# N32G41x register map
Vendor: Nsingtech Ltd.; File version: 1.0
CPU: CM4 r0p1, little endian, no MPU, no FPU, 4 interrupt priority bits
Registers are 32-bit, read-write, reset 0x0 unless marked. A register's access mark holds for its fields unless they carry their own. Offsets are from the block's base; [hi:lo] are bit positions; {n}, {i} and the like mark numbered series.

## GPIOC — GPIO Port C
Base 0x40021600
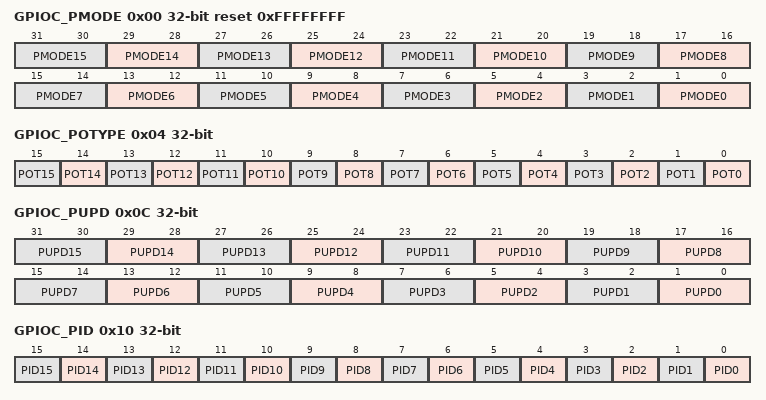
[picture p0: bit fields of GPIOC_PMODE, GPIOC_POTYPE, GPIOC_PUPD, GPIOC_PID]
0x00 GPIOC_PMODE reset 0xFFFFFFFF — GPIOC Port Mode Register
  [2n+1:2n] PMODE{n} (n=0..15) — Port C mode for pin {n}
0x04 GPIOC_POTYPE — GPIOC Port Output Type Register
  [n] POT{n} (n=0..15) — Port C output type for pin {n}
0x0C GPIOC_PUPD — GPIOC Port Pull-Up/Pull-Down Register
  [2n+1:2n] PUPD{n} (n=0..15) — Port C pull-up/pull-down for pin {n}
0x10 GPIOC_PID ro — GPIOC Port Input Data Register
  [n] PID{n} (n=0..15) — Port C input data for pin {n}
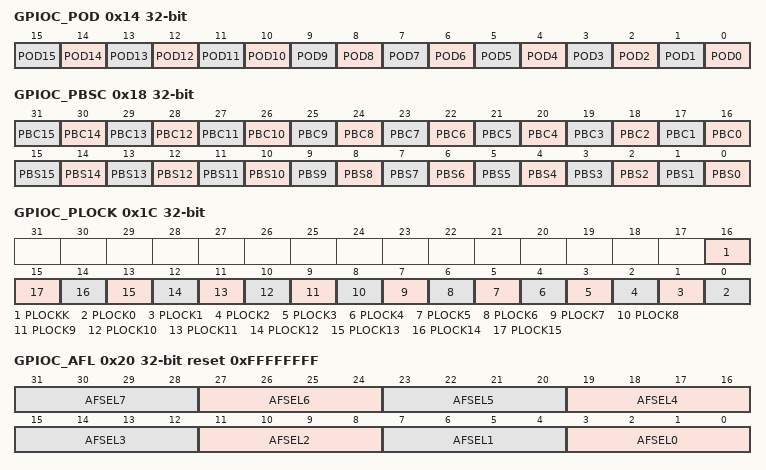
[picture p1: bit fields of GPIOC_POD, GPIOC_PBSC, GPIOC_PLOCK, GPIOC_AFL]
0x14 GPIOC_POD — GPIOC Port Output Data Register
  [n] POD{n} (n=0..15) — Port C output data for pin {n}
0x18 GPIOC_PBSC wo — GPIOC Port Bit Set/Clear Register
  [n+16] PBC{n} (n=0..15) — Port C clear bit {n}
  [n] PBS{n} (n=0..15) — Port C set bit {n}
0x1C GPIOC_PLOCK — GPIOC Port Configuration Lock Register
  [16] PLOCKK — Port configuration lock key
  [n] PLOCK{n} (n=0..15) — Port C configuration lock for pin {n}
0x20 GPIOC_AFL reset 0xFFFFFFFF — GPIOC Alternate Function Low Register
  [4n+3:4n] AFSEL{n} (n=0..7) — Port C alternate function for pin {n}
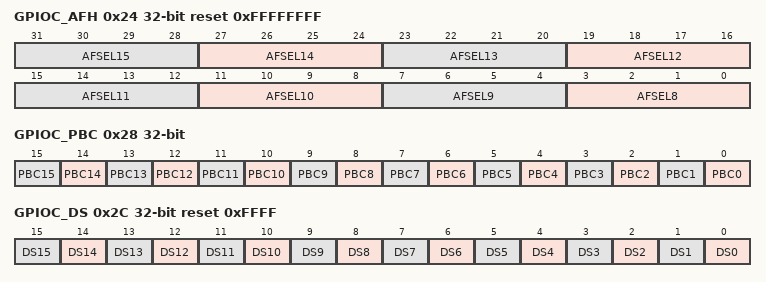
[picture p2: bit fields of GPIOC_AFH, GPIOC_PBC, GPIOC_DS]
0x24 GPIOC_AFH reset 0xFFFFFFFF — GPIOC Alternate Function High Register
  [4n-29:4n-32] AFSEL{n} (n=8..15) — Port C alternate function for pin {n}
0x28 GPIOC_PBC wo — GPIOC Port Bit Clear Register
  [n] PBC{n} (n=0..15) — Port C clear output bit {n}
0x2C GPIOC_DS reset 0xFFFF — GPIOC Drive Strength Register
  [n] DS{n} (n=0..15) — Port C drive strength for pin {n}

## GPIOD — GPIO Port D
Base 0x40021700
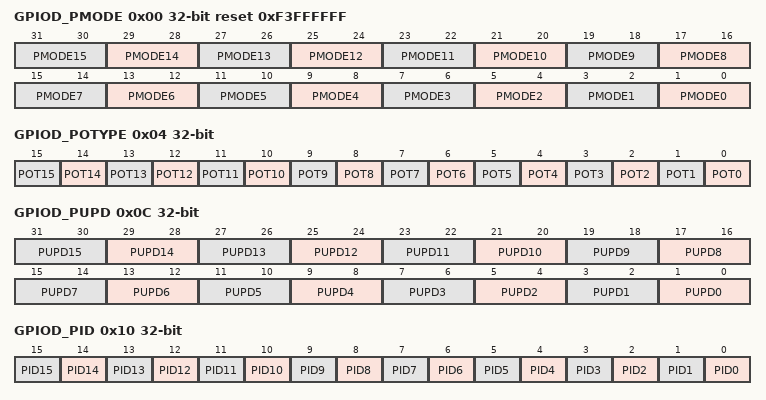
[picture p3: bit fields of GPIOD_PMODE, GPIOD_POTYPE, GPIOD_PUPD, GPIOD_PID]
0x00 GPIOD_PMODE reset 0xF3FFFFFF — GPIOD Port Mode Register
  [2n+1:2n] PMODE{n} (n=0..15) — Port D mode for pin {n}
0x04 GPIOD_POTYPE — GPIOD Port Output Type Register
  [n] POT{n} (n=0..15) — Port D output type for pin {n}
0x0C GPIOD_PUPD — GPIOD Port Pull-Up/Pull-Down Register
  [2n+1:2n] PUPD{n} (n=0..15) — Port D pull-up/pull-down for pin {n}
0x10 GPIOD_PID ro — GPIOD Port Input Data Register
  [n] PID{n} (n=0..15) — Port D input data for pin {n}
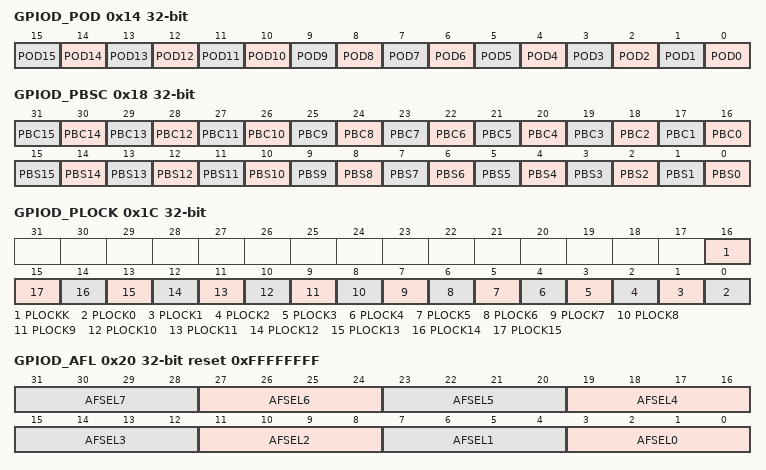
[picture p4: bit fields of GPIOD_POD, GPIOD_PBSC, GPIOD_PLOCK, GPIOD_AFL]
0x14 GPIOD_POD — GPIOD Port Output Data Register
  [n] POD{n} (n=0..15) — Port D output data for pin {n}
0x18 GPIOD_PBSC wo — GPIOD Port Bit Set/Clear Register
  [n+16] PBC{n} (n=0..15) — Port D clear bit {n}
  [n] PBS{n} (n=0..15) — Port D set bit {n}
0x1C GPIOD_PLOCK — GPIOD Port Configuration Lock Register
  [16] PLOCKK — Port configuration lock key
  [n] PLOCK{n} (n=0..15) — Port D configuration lock for pin {n}
0x20 GPIOD_AFL reset 0xFFFFFFFF — GPIOD Alternate Function Low Register
  [4n+3:4n] AFSEL{n} (n=0..7) — Port D alternate function for pin {n}
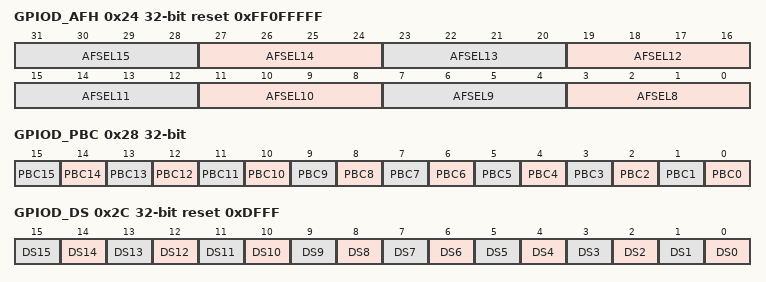
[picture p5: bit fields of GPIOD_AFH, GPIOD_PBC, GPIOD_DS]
0x24 GPIOD_AFH reset 0xFF0FFFFF — GPIOD Alternate Function High Register
  [4n-29:4n-32] AFSEL{n} (n=8..15) — Port D alternate function for pin {n}
0x28 GPIOD_PBC wo — GPIOD Port Bit Clear Register
  [n] PBC{n} (n=0..15) — Port D clear output bit {n}
0x2C GPIOD_DS reset 0xDFFF — GPIOD Drive Strength Register
  [n] DS{n} (n=0..15) — Port D drive strength for pin {n}

## AFIO — Alternate Function I/O
Base 0x40021800
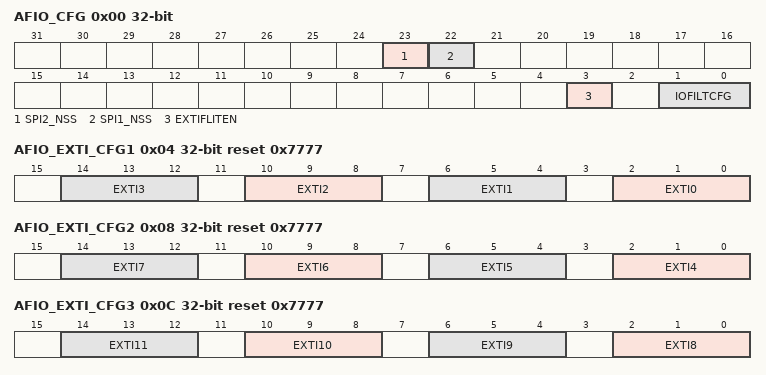
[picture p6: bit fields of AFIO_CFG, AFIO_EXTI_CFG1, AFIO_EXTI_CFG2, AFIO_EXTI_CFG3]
0x00 AFIO_CFG — AFIO Configuration Register
  [23] SPI2_NSS — SPI2 NSS mode
  [22] SPI1_NSS — SPI1 NSS mode
  [3] EXTIFLITEN — EXTI line filter enable
  [1:0] IOFILTCFG — IO filter control
0x04 AFIO_EXTI_CFG1 reset 0x7777 — AFIO EXTI Configuration Register 1
  [4n+2:4n] EXTI{n} (n=0..3) — EXTI{n} configuration
0x08 AFIO_EXTI_CFG2 reset 0x7777 — AFIO EXTI Configuration Register 2
  [4n-14:4n-16] EXTI{n} (n=4..7) — EXTI{n} configuration
0x0C AFIO_EXTI_CFG3 reset 0x7777 — AFIO EXTI Configuration Register 3
  [4n-30:4n-32] EXTI{n} (n=8..11) — EXTI{n} configuration
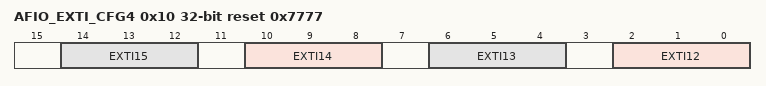
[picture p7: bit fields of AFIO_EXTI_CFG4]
0x10 AFIO_EXTI_CFG4 reset 0x7777 — AFIO EXTI Configuration Register 4
  [4n-46:4n-48] EXTI{n} (n=12..15) — EXTI{n} configuration
0x14 AFIO_DIGEFT_CFG1 — AFIO PA Digital Filter Configuration Register
  [15:0] DIGEFTEN — PA digital filter enable
0x18 AFIO_DIGEFT_CFG2 — AFIO PB Digital Filter Configuration Register
  [15:0] DIGEFTEN — PB digital filter enable
0x1C AFIO_DIGEFT_CFG3 — AFIO PC Digital Filter Configuration Register
  [15:0] DIGEFTEN — PC digital filter enable
0x20 AFIO_DIGEFT_CFG4 — AFIO PD Digital Filter Configuration Register
  [15:0] DIGEFTEN — PD digital filter enable

## PWR — Power Control
Base 0x40007000
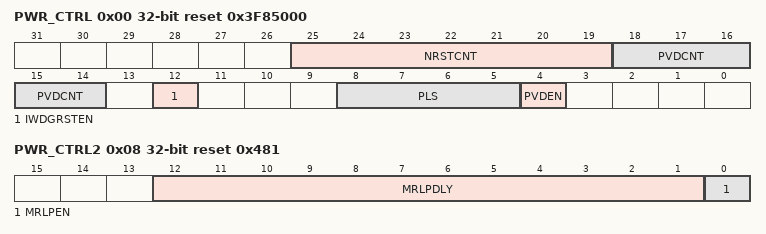
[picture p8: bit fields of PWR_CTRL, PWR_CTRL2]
0x00 PWR_CTRL reset 0x3F85000 — PWR Control Register
  [25:19] NRSTCNT — NRST pin filter width
  [18:14] PVDCNT — PVD filter width
  [12] IWDGRSTEN — IWDG reset enable control
  [8:5] PLS — PVD alarm voltage level selection
  [4] PVDEN — PVD enable control
0x04 PWR_CTRLSTS ro — PWR Control/Status Register
  [2] PVDO — PVD module detection output
0x08 PWR_CTRL2 reset 0x481 — PWR Control Register 2
  [12:1] MRLPDLY — MR LP control delay
  [0] MRLPEN — MR LOWPOWER mode control

## FLASH — FLASH Memory Controller
Base 0x40022000
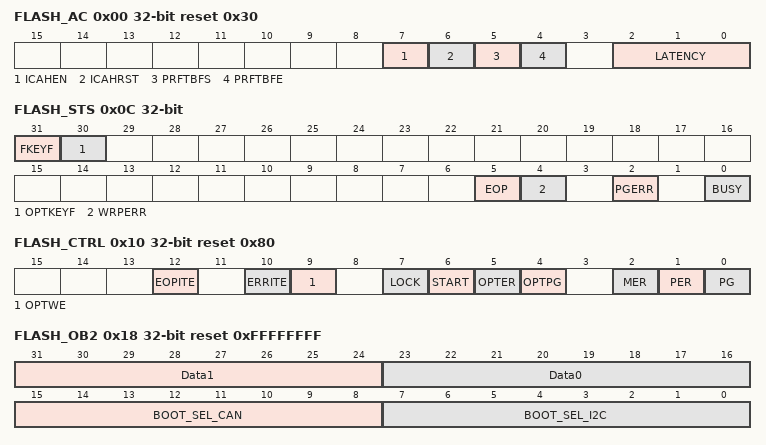
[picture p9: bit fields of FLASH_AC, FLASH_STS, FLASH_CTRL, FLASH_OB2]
0x00 FLASH_AC reset 0x30 — FLASH Access Control Register
  [7] ICAHEN — Icache enable
  [6] ICAHRST — Icache reset
  [5] PRFTBFS ro — Prefetch buffer status
  [4] PRFTBFE — Prefetch buffer enable
  [2:0] LATENCY
0x04 FLASH_KEY wo
  [31:0] FKEY — Flash unlock key
0x08 FLASH_OPTKEY wo — FLASH Option Key Register
  [31:0] OPTKEY — Option byte unlock key
0x0C FLASH_STS — FLASH Status Register
  [31] FKEYF ro — FLASH unlock KEY1 flag
  [30] OPTKEYF ro — Option byte unlock KEY1 flag
  [5] EOP — End of operation
  [4] WRPERR — Write protection error
  [2] PGERR — Programming error
  [0] BUSY ro
0x10 FLASH_CTRL reset 0x80 — FLASH Control Register
  [12] EOPITE — End of operation interrupt enable
  [10] ERRITE — Error interrupt enable
  [9] OPTWE — Option byte write enable
  [7] LOCK
  [6] START — Start erase
  [5] OPTER — Option byte erase
  [4] OPTPG — Option byte programming
  [2] MER — Mass erase
  [1] PER — Page erase
  [0] PG — Programming
0x14 FLASH_ADD wo — FLASH Address Register
  [31:0] FADD — Flash address
0x18 FLASH_OB2 ro reset 0xFFFFFFFF — FLASH Option Byte Register 2
  [31:24] Data1
  [23:16] Data0
  [15:8] BOOT_SEL_CAN — BOOT CAN pin selection
  [7:0] BOOT_SEL_I2C — BOOT I2C pin selection
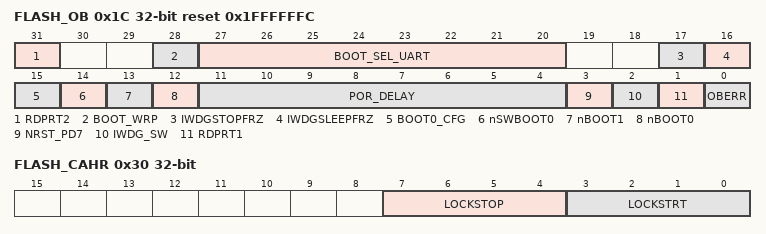
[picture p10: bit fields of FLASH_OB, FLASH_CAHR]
0x1C FLASH_OB ro reset 0x1FFFFFFC — FLASH Option Byte Register
  [31] RDPRT2 — Read protection L2 level
  [28] BOOT_WRP — BOOT write protection
  [27:20] BOOT_SEL_UART — BOOT UART pin selection
  [17] IWDGSTOPFRZ — IWDG stop mode freeze enable
  [16] IWDGSLEEPFRZ — IWDG sleep mode freeze enable
  [15] BOOT0_CFG — BOOT0 default state
  [14] nSWBOOT0 — nSWBOOT0 configuration
  [13] nBOOT1 — nBOOT1 configuration
  [12] nBOOT0 — nBOOT0 configuration
  [11:4] POR_DELAY — POR CPU reset delay time
  [3] NRST_PD7 — PD7 pin configuration
  [2] IWDG_SW — Watchdog configuration
  [1] RDPRT1 — Read protection L1 level
  [0] OBERR — Option byte error
0x20 FLASH_WRP reset 0xFFFFFFFF — FLASH Write Protection Register
  [31:0] WRPT — Write protection
0x30 FLASH_CAHR — FLASH Cache Register
  [7:4] LOCKSTOP — iCache lock stop
  [3:0] LOCKSTRT — iCache lock start

## DBG — Debug Support
Base 0xE0042000
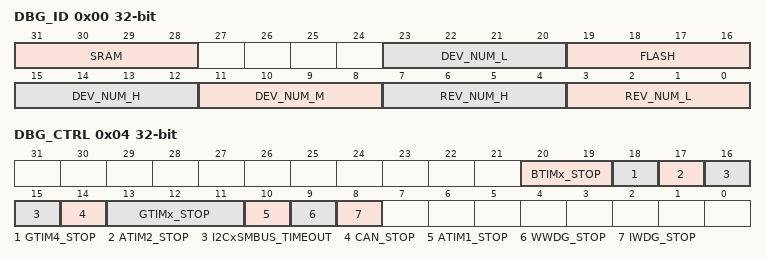
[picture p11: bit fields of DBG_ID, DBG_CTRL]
0x00 DBG_ID ro
  [31:28] SRAM — SRAM capacity
  [23:20] DEV_NUM_L — Device number low 4 bits
  [19:16] FLASH — FLASH capacity
  [15:12] DEV_NUM_H — Device number high 4 bits
  [11:8] DEV_NUM_M — Device number middle 4 bits
  [7:4] REV_NUM_H — Revision number high 4 bits
  [3:0] REV_NUM_L — Revision number low 4 bits
0x04 DBG_CTRL — DBG Control Register
  [20:19] BTIMx_STOP — BTIMx debug stop
  [18] GTIM4_STOP — GTIM4 debug stop
  [17] ATIM2_STOP — ATIM2 debug stop
  [16:15] I2CxSMBUS_TIMEOUT — I2Cx SMBUS timeout stop
  [14] CAN_STOP — CAN debug stop
  [13:11] GTIMx_STOP — GTIMx debug stop (x=3,2,1)
  [10] ATIM1_STOP — ATIM1 debug stop
  [9] WWDG_STOP — WWDG debug stop
  [8] IWDG_STOP — IWDG debug stop
